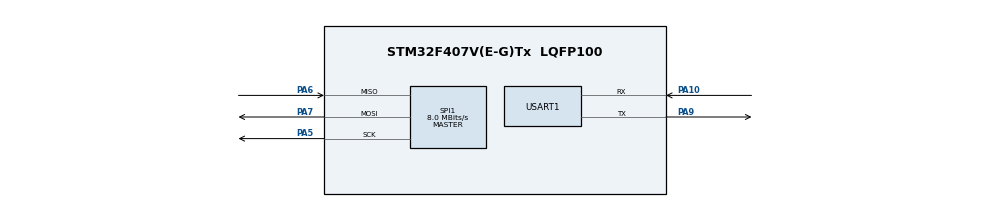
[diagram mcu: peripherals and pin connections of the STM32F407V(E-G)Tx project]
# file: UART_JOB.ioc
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Mcu.Family=STM32F4
Mcu.Name=STM32F407V(E-G)Tx
Mcu.Package=LQFP100
NVIC.PriorityGroup=NVIC_PRIORITYGROUP_4
PA10.Mode=Multiprocessor_communication
PA10.Signal=USART1_RX
PA5.Mode=Full_Duplex_Master
PA5.Signal=SPI1_SCK
PA6.Mode=Full_Duplex_Master
PA6.Signal=SPI1_MISO
PA7.Mode=Full_Duplex_Master
PA7.Signal=SPI1_MOSI
PA9.Mode=Multiprocessor_communication
PA9.Signal=USART1_TX
PH0-OSC_IN.Mode=HSE-External-Oscillator
PH0-OSC_IN.Signal=RCC_OSC_IN
PH1-OSC_OUT.Mode=HSE-External-Oscillator
PH1-OSC_OUT.Signal=RCC_OSC_OUT
ProjectManager.HeapSize=0x200
ProjectManager.StackSize=0x400
ProjectManager.TargetToolchain=Makefile
RCC.AHBFreq_Value=16000000
RCC.APB1Freq_Value=16000000
RCC.APB2Freq_Value=16000000
RCC.CortexFreq_Value=16000000
RCC.HSE_VALUE=25000000
RCC.HSI_VALUE=16000000
RCC.LSE_VALUE=32768
RCC.SYSCLKFreq_VALUE=16000000
RCC.VCOOutputFreq_Value=192000000
SPI1.CalculateBaudRate=8.0 MBits/s
SPI1.Direction=SPI_DIRECTION_2LINES
SPI1.Mode=SPI_MODE_MASTER
SPI1.VirtualType=VM_MASTER
USART1.VirtualMode=VM_ASYNC
board=custom

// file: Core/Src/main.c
/* USER CODE BEGIN Header */
/**
  ******************************************************************************
  * @file           : main.c
  * @brief          : Main program body
  ******************************************************************************
  * @attention
  *
  * Copyright (c) 2023 STMicroelectronics.
  * All rights reserved.
  *
  * This software is licensed under terms that can be found in the LICENSE file
  * in the root directory of this software component.
  * If no LICENSE file comes with this software, it is provided AS-IS.
  *
  ******************************************************************************
  */
/* USER CODE END Header */
#include "main.h"

SPI_HandleTypeDef hspi1;

void SystemClock_Config(void);
static void MX_GPIO_Init(void);
static void MX_USART1_UART_Init(void);
static void MX_SPI1_Init(void);

int main(void)
{
  /* USER CODE BEGIN 1 */
  uint16_t i=0;
  /* USER CODE END 1 */

  /* MCU Configuration--------------------------------------------------------*/

  /* Reset of all peripherals, Initializes the Flash interface and the Systick. */
  HAL_Init();

  /* Configure the system clock */
  SystemClock_Config();

  /* Initialize all configured peripherals */
  MX_GPIO_Init();
  MX_USART1_UART_Init();
  MX_SPI1_Init();
  /* USER CODE BEGIN 2 */
  uint8_t str1[5] = { 0 };

  /* USER CODE END 2 */

  /* Infinite loop */
  /* USER CODE BEGIN WHILE */
  while (1)
  {

    HAL_SPI_Transmit(&hspi1, "test",5, HAL_MAX_DELAY);
    /* USER CODE END WHILE */

  }
}

void SystemClock_Config(void)
{
  LL_FLASH_SetLatency(LL_FLASH_LATENCY_0);
  while(LL_FLASH_GetLatency()!= LL_FLASH_LATENCY_0)
  {
  }
  LL_PWR_SetRegulVoltageScaling(LL_PWR_REGU_VOLTAGE_SCALE1);
  LL_RCC_HSI_SetCalibTrimming(16);
  LL_RCC_HSI_Enable();

   /* Wait till HSI is ready */

  LL_RCC_SetAHBPrescaler(LL_RCC_SYSCLK_DIV_1);
  LL_RCC_SetAPB1Prescaler(LL_RCC_APB1_DIV_1);
  LL_RCC_SetAPB2Prescaler(LL_RCC_APB2_DIV_1);
  LL_RCC_SetSysClkSource(LL_RCC_SYS_CLKSOURCE_HSI);

   /* Wait till System clock is ready */
  while(LL_RCC_GetSysClkSource() != LL_RCC_SYS_CLKSOURCE_STATUS_HSI)
  {

  }
  LL_SetSystemCoreClock(16000000);

   /* Update the time base */
  if (HAL_InitTick (TICK_INT_PRIORITY) != HAL_OK)
  {
    Error_Handler();
  }
}

static void MX_SPI1_Init(void)
{

  /* SPI1 parameter configuration*/
  hspi1.Instance = SPI1;
  hspi1.Init.Mode = SPI_MODE_MASTER;
  hspi1.Init.Direction = SPI_DIRECTION_2LINES;
  hspi1.Init.DataSize = SPI_DATASIZE_8BIT;
  hspi1.Init.CLKPolarity = SPI_POLARITY_LOW;
  hspi1.Init.CLKPhase = SPI_PHASE_1EDGE;
  hspi1.Init.NSS = SPI_NSS_SOFT;
  hspi1.Init.BaudRatePrescaler = SPI_BAUDRATEPRESCALER_2;
  hspi1.Init.FirstBit = SPI_FIRSTBIT_MSB;
  hspi1.Init.TIMode = SPI_TIMODE_DISABLE;
  hspi1.Init.CRCCalculation = SPI_CRCCALCULATION_DISABLE;
  hspi1.Init.CRCPolynomial = 10;
  if (HAL_SPI_Init(&hspi1) != HAL_OK)
  {
    Error_Handler();
  }

}

static void MX_USART1_UART_Init(void)
{

  LL_USART_InitTypeDef USART_InitStruct = {0};

  LL_GPIO_InitTypeDef GPIO_InitStruct = {0};

  /* Peripheral clock enable */
  LL_APB2_GRP1_EnableClock(LL_APB2_GRP1_PERIPH_USART1);

  LL_AHB1_GRP1_EnableClock(LL_AHB1_GRP1_PERIPH_GPIOA);
  /**USART1 GPIO Configuration
  PA9   ------> USART1_TX
  PA10   ------> USART1_RX
  */
  GPIO_InitStruct.Pin = LL_GPIO_PIN_9|LL_GPIO_PIN_10;
  GPIO_InitStruct.Mode = LL_GPIO_MODE_ALTERNATE;
  GPIO_InitStruct.Speed = LL_GPIO_SPEED_FREQ_VERY_HIGH;
  GPIO_InitStruct.OutputType = LL_GPIO_OUTPUT_PUSHPULL;
  GPIO_InitStruct.Pull = LL_GPIO_PULL_NO;
  GPIO_InitStruct.Alternate = LL_GPIO_AF_7;
  LL_GPIO_Init(GPIOA, &GPIO_InitStruct);

  USART_InitStruct.BaudRate = 115200;
  USART_InitStruct.DataWidth = LL_USART_DATAWIDTH_8B;
  USART_InitStruct.StopBits = LL_USART_STOPBITS_1;
  USART_InitStruct.Parity = LL_USART_PARITY_NONE;
  USART_InitStruct.TransferDirection = LL_USART_DIRECTION_TX_RX;
  USART_InitStruct.OverSampling = LL_USART_OVERSAMPLING_16;
  LL_USART_Init(USART1, &USART_InitStruct);
  LL_USART_SetWakeUpMethod(USART1, LL_USART_WAKEUP_IDLELINE);
  LL_USART_ConfigMultiProcessMode(USART1);
  LL_USART_Enable(USART1);

}

static void MX_GPIO_Init(void)
{

  /* GPIO Ports Clock Enable */
  LL_AHB1_GRP1_EnableClock(LL_AHB1_GRP1_PERIPH_GPIOH);
  LL_AHB1_GRP1_EnableClock(LL_AHB1_GRP1_PERIPH_GPIOA);

}

void Error_Handler(void)
{
  __disable_irq();
  while (1)
  {
  }
}
